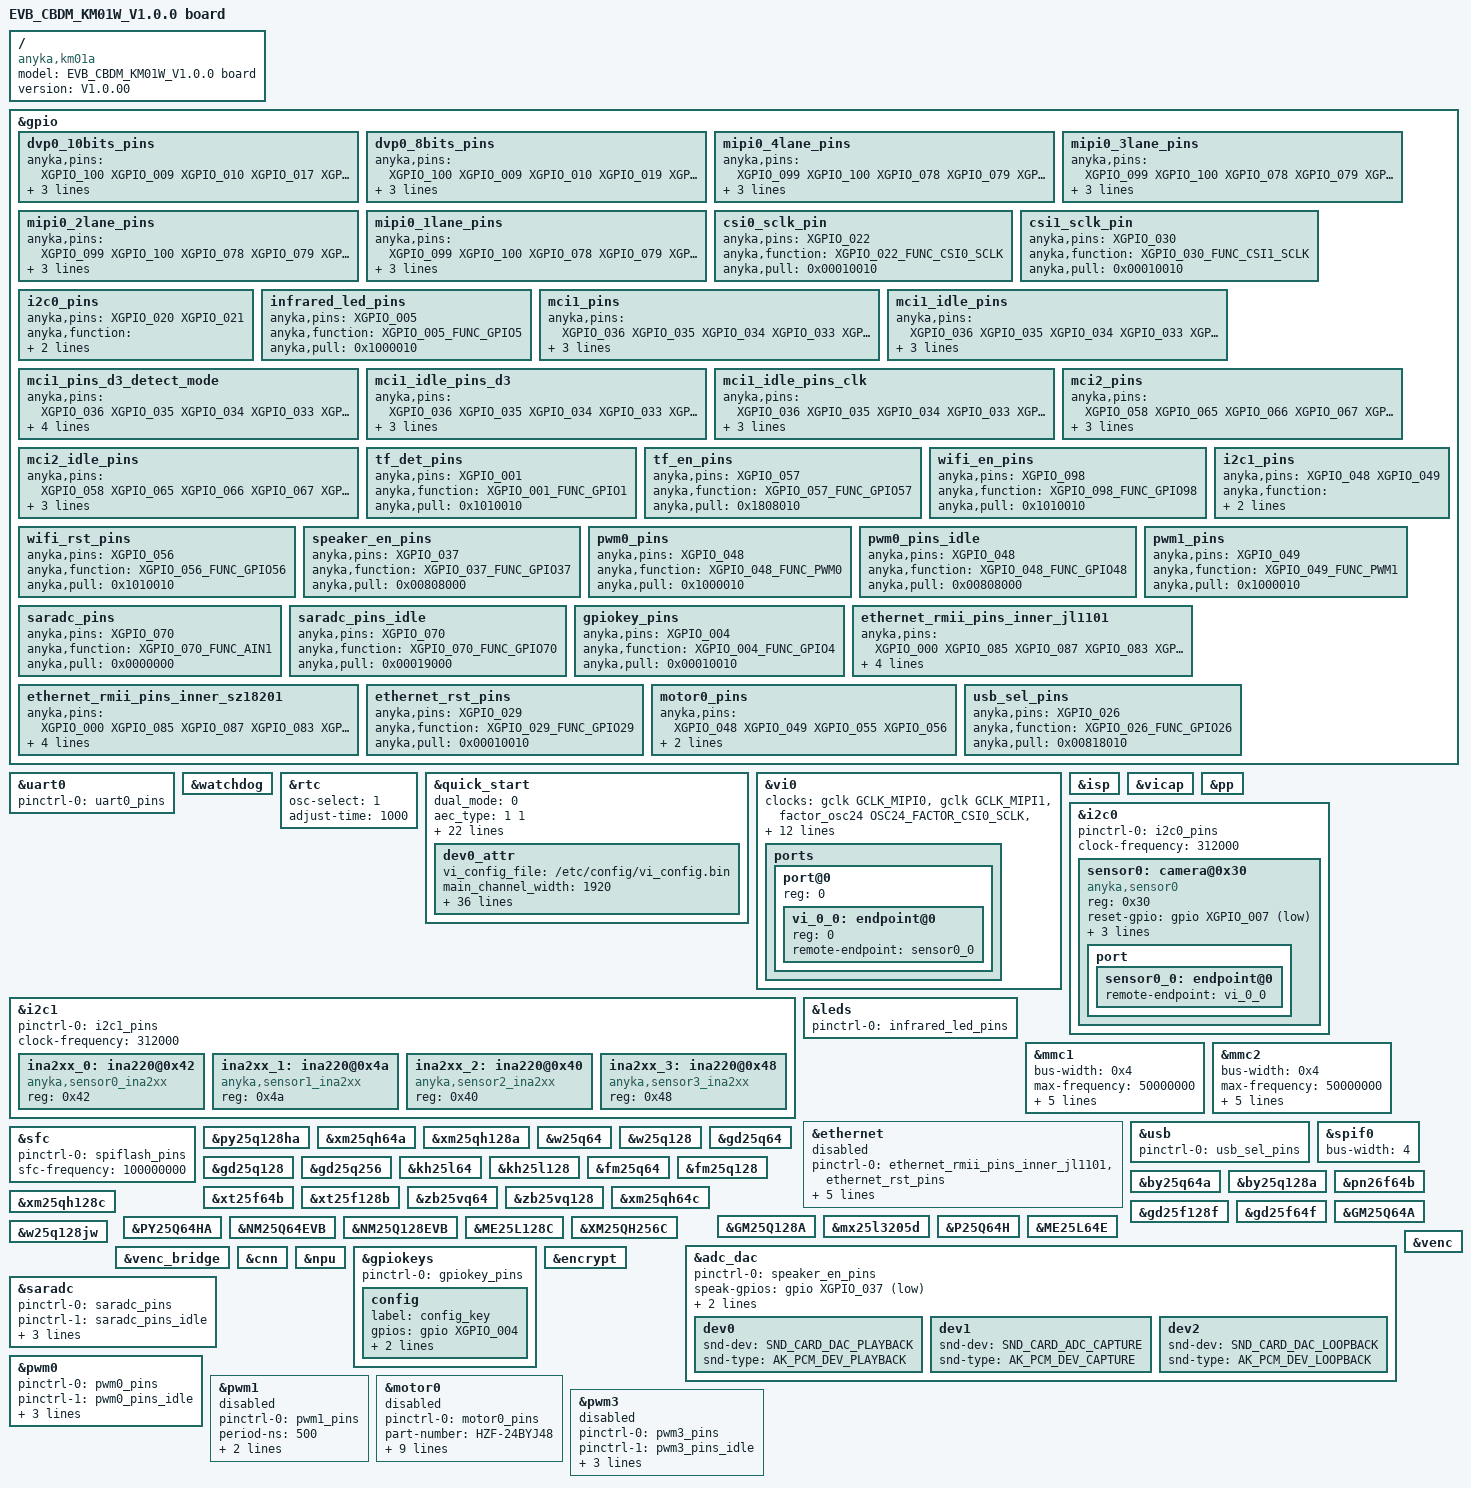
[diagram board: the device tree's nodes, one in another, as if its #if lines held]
/*
 * KM01W dev board dts
 *
 * Copyright (C) 2020 Anyka(Guangzhou) Microelectronics Technology Co., Ltd.
 *
 * This program is free software; you can redistribute it and/or modify
 * it under the terms of the GNU General Public License as published by
 * the Free Software Foundation; either version 2 of the License, or
 * (at your option) any later version.
 *
 * This program is distributed in the hope that it will be useful,
 * but WITHOUT ANY WARRANTY; without even the implied warranty of
 * MERCHANTABILITY or FITNESS FOR A PARTICULAR PURPOSE.  See the
 * GNU General Public License for more details.
 */

/dts-v1/;
#include "anycloud_km01a.dtsi"
#include "anycloud_norflash.dtsi"
//#include "anycloud_nandflash.dtsi"

/ {
    compatible = "anyka,km01a";
    model = "EVB_CBDM_KM01W_V1.0.0 board";
    version = "V1.0.00";
};

&gpio {
    /*
    * "anyka,function": func index, please refer to dt-bindings/pinctrl/ak3918av100_pinctrl.h
    * "anyka,pull": configuration of the pins
    * bit[7:0]: pull up/down configuration
    *     bit[0]: pull up or pull down selection, 1 means select pull down, 0 means select pull up
    *     bit[4]: pull up or pull down enable, 1 means enable pull up&down function, 0 means disable fuction
    * !!! Notice that not all pin support pull up and pull down. Please refer to the programer's guide.
    * bit[11:8]: driver strength configuration.
    *     bit[9:8] drive strength.
    * bit[12:15] gpio direction
    *     bit[12]: direction. 0 is output, 1 is input
    *     bit[15]: enable direction. 1 is enable
    * bit[19:16]: input enable configuration
    *     bit[16]: 1 means enable input, 0 means disable input.
    * bit[20-23]: gpio output level
    *     bit[20]: 0 is low level, 1 is high level
    *     bit[23]: enable gpio output level. 1 is enable
    * bit[31:24]: pin slew rate configuration
    *     bit[24]: 1 means fast slew rate, 0 means slow slew rate.
    * !!! Notice OTHER bits which not mentioned please set to 0.
    */

    dvp0_10bits_pins: dvp0_10bits_pins {
        anyka,pins = <XGPIO_100		//pclk
                         XGPIO_009	//hsync
                         XGPIO_010	//vsync
                         XGPIO_017	//d0
                         XGPIO_018  //d1
                         XGPIO_019	//d2
                         XGPIO_020	//d3
                         XGPIO_023	//d4
                         XGPIO_021	//d5
                         XGPIO_078	//d6
                         XGPIO_099	//d7
                         XGPIO_102	//d8
                         XGPIO_101>;//d9

        anyka,function = <XGPIO_100_FUNC_CSI_CLK
                            XGPIO_009_FUNC_CSI_HSYNC
                            XGPIO_010_FUNC_CSI_VSYNC
                            XGPIO_017_FUNC_CSI_D0
                            XGPIO_018_FUNC_CSI_D1
                            XGPIO_019_FUNC_CSI_D2
                            XGPIO_020_FUNC_CSI_D3
                            XGPIO_023_FUNC_CSI_D4
                            XGPIO_021_FUNC_CSI_D5
                            XGPIO_078_FUNC_CSI_D6
                            XGPIO_099_FUNC_CSI_D7
                            XGPIO_102_FUNC_CSI_D8
                            XGPIO_101_FUNC_CSI_D9>;
        anyka,pull = <0x00010010>;
    };

    dvp0_8bits_pins: dvp0_8bits_pins {
        anyka,pins = <   XGPIO_100
                         XGPIO_009
                         XGPIO_010
                         XGPIO_019	//d2
                         XGPIO_020	//d3
                         XGPIO_023	//d4
                         XGPIO_021	//d5
                         XGPIO_078	//d6
                         XGPIO_099	//d7
                         XGPIO_102	//d8
                         XGPIO_101>;//d9
        anyka,function = <  XGPIO_100_FUNC_CSI_CLK
                            XGPIO_009_FUNC_CSI_HSYNC
                            XGPIO_010_FUNC_CSI_VSYNC
                            XGPIO_019_FUNC_CSI_D2
                            XGPIO_020_FUNC_CSI_D3
                            XGPIO_023_FUNC_CSI_D4
                            XGPIO_021_FUNC_CSI_D5
                            XGPIO_078_FUNC_CSI_D6
                            XGPIO_099_FUNC_CSI_D7
                            XGPIO_102_FUNC_CSI_D8
                            XGPIO_101_FUNC_CSI_D9>;
        anyka,pull = <0x00010010>;
    };

	mipi0_4lane_pins: mipi0_4lane_pins {
		anyka,pins = <XGPIO_099
                        XGPIO_100
                        XGPIO_078
                        XGPIO_079
                        XGPIO_101
                        XGPIO_102
						XGPIO_103
                        XGPIO_104
						XGPIO_072
                        XGPIO_073>;
        anyka,function = <XGPIO_099_FUNC_MIPI_RX_L0P
                            XGPIO_100_FUNC_MIPI_RX_L0N
                            XGPIO_078_FUNC_MIPI_RX_L1P
                            XGPIO_079_FUNC_MIPI_RX_L1N
                            XGPIO_101_FUNC_MIPI_RX_L2P
                            XGPIO_102_FUNC_MIPI_RX_L2N
							XGPIO_103_FUNC_MIPI_RX_L3P
							XGPIO_104_FUNC_MIPI_RX_L3N
							XGPIO_072_FUNC_MIPI_RX_L4P
							XGPIO_073_FUNC_MIPI_RX_L4N>;
        anyka,pull = <0x00010010>;
	};

	mipi0_3lane_pins: mipi0_3lane_pins {
		anyka,pins = <XGPIO_099
                        XGPIO_100
                        XGPIO_078
                        XGPIO_079
                        XGPIO_101
                        XGPIO_102
						XGPIO_103
                        XGPIO_104
						XGPIO_072
                        XGPIO_073>;
        anyka,function = <XGPIO_099_FUNC_MIPI_RX_L0P
                            XGPIO_100_FUNC_MIPI_RX_L0N
                            XGPIO_078_FUNC_MIPI_RX_L1P
                            XGPIO_079_FUNC_MIPI_RX_L1N
                            XGPIO_101_FUNC_MIPI_RX_L2P
                            XGPIO_102_FUNC_MIPI_RX_L2N
							XGPIO_103_FUNC_MIPI_RX_L3P
							XGPIO_104_FUNC_MIPI_RX_L3N
							XGPIO_072_FUNC_MIPI_RX_L4P
							XGPIO_073_FUNC_MIPI_RX_L4N>;
        anyka,pull = <0x00010010>;
	};

	mipi0_2lane_pins: mipi0_2lane_pins {
		anyka,pins = <XGPIO_099
                        XGPIO_100
                        XGPIO_078
                        XGPIO_079
                        XGPIO_101
                        XGPIO_102>;
        anyka,function = <XGPIO_099_FUNC_MIPI_RX_L0P
                            XGPIO_100_FUNC_MIPI_RX_L0N
                            XGPIO_078_FUNC_MIPI_RX_L1P
                            XGPIO_079_FUNC_MIPI_RX_L1N
                            XGPIO_101_FUNC_MIPI_RX_L2P
                            XGPIO_102_FUNC_MIPI_RX_L2N>;
        anyka,pull = <0x00010010>;
	};

	mipi0_1lane_pins: mipi0_1lane_pins {
		anyka,pins = <XGPIO_099
                        XGPIO_100
                        XGPIO_078
                        XGPIO_079
                        XGPIO_101
                        XGPIO_102>;
        anyka,function = <XGPIO_099_FUNC_MIPI_RX_L0P
                            XGPIO_100_FUNC_MIPI_RX_L0N
                            XGPIO_078_FUNC_MIPI_RX_L1P
                            XGPIO_079_FUNC_MIPI_RX_L1N
                            XGPIO_101_FUNC_MIPI_RX_L2P
                            XGPIO_102_FUNC_MIPI_RX_L2N>;
        anyka,pull = <0x00010010>;
	};

    csi0_sclk_pin: csi0_sclk_pin {
        anyka,pins = <XGPIO_022>;
        anyka,function = <XGPIO_022_FUNC_CSI0_SCLK>;
        anyka,pull = <0x00010010>;
    };

    csi1_sclk_pin: csi1_sclk_pin {
        anyka,pins = <XGPIO_030>;
        anyka,function = <XGPIO_030_FUNC_CSI1_SCLK>;
        anyka,pull = <0x00010010>;
    };

    i2c0_pins: i2c0_pins {
        anyka,pins = <XGPIO_020 XGPIO_021>;
        anyka,function = <XGPIO_020_FUNC_TWI0_SDA XGPIO_021_FUNC_TWI0_SCL>;
        anyka,pull = <0x1010010>;
    };

    infrared_led_pins: infrared_led_pins {
        anyka,pins = <XGPIO_005>;
        anyka,function = <XGPIO_005_FUNC_GPIO5>;
        anyka,pull = <0x1000010>;
    };
/*
    state_led_pin: state_led_pin {
        anyka,pins = <XGPIO_005>;
        anyka,function = <XGPIO_005_FUNC_GPIO5>;
        anyka,pull = <0x1000010>;
    };
*/
    mci1_pins: mci1_pins {
        anyka,pins = <XGPIO_036
                        XGPIO_035
                        XGPIO_034
                        XGPIO_033
                        XGPIO_032
                        XGPIO_031>;
        anyka,function = <XGPIO_036_FUNC_SDIO0_DATA1
                            XGPIO_035_FUNC_SDIO0_DATA0
                            XGPIO_034_FUNC_SDIO0_MCLK
                            XGPIO_033_FUNC_SDIO0_CMD
                            XGPIO_032_FUNC_SDIO0_DATA3
                            XGPIO_031_FUNC_SDIO0_DATA2>;
        anyka,pull = <0x10010>;
    };

    /*
       when not use tf card, set to idle state,
       to protect tf card and extend it's life.
    */
    mci1_idle_pins: mci1_idle_pins {
        anyka,pins = <XGPIO_036
                        XGPIO_035
                        XGPIO_034
                        XGPIO_033
                        XGPIO_032
                        XGPIO_031>;
        anyka,function = <XGPIO_036_FUNC_GPIO36
                            XGPIO_035_FUNC_GPIO35
                            XGPIO_034_FUNC_GPIO34
                            XGPIO_033_FUNC_GPIO33
                            XGPIO_032_FUNC_GPIO32
                            XGPIO_031_FUNC_GPIO31>;
        anyka,pull = <0x11>;
    };

    /* 
     *  When using DATA3 as plugin and plugoff detect:
     *  1. Set XGPIO_032_FUNC_SDIO0_DATA3 pull up disable and pull down disable
     *  2. Using PULLDOWN RESISTANCE on PCB, for example, 510   KΩ.
    */      
    mci1_pins_d3_detect_mode: mci1_pins_d3_detect_mode {
        anyka,pins = <XGPIO_036
                        XGPIO_035
                        XGPIO_034
                        XGPIO_033
                        XGPIO_032
                        XGPIO_031>;
        anyka,function = <XGPIO_036_FUNC_SDIO0_DATA1
                            XGPIO_035_FUNC_SDIO0_DATA0
                            XGPIO_034_FUNC_SDIO0_MCLK
                            XGPIO_033_FUNC_SDIO0_CMD
                            XGPIO_032_FUNC_SDIO0_DATA3
                            XGPIO_031_FUNC_SDIO0_DATA2>;
        anyka,pull = <  0x10010 
                        0x10010
                        0x10010
                        0x10010
                        0x10001  /* disable pull down and pull up */
                        0x10010 >;
    };

    /*
       when not use tf card, set to idle state, the pin set to gpio function except dat3 pin.
       to protect tf card, extend it's life.
    */
    mci1_idle_pins_d3: mci1_idle_pins_d3 {
        anyka,pins = <XGPIO_036
                        XGPIO_035
                        XGPIO_034
                        XGPIO_033
                        XGPIO_032
                        XGPIO_031>;
        anyka,function = <XGPIO_036_FUNC_GPIO36
                            XGPIO_035_FUNC_GPIO35
                            XGPIO_034_FUNC_GPIO34
                            XGPIO_033_FUNC_GPIO33
                            XGPIO_032_FUNC_SDIO0_DATA3
                            XGPIO_031_FUNC_GPIO31>;
        anyka,pull = <  0x11
                        0x11
                        0x11
                        0x11
                        0x10001  /* disable pull down and pull up */
                        0x11 >;
    };

    /*
       when not use tf card, set to idle state, the pin set to gpio function except mclk pin.
       to protect tf card, extend it's life.
    */
    mci1_idle_pins_clk: mci1_idle_pins_clk {
        anyka,pins = <XGPIO_036
                        XGPIO_035
                        XGPIO_034
                        XGPIO_033
                        XGPIO_032
                        XGPIO_031>;
        anyka,function = <XGPIO_036_FUNC_GPIO36
                            XGPIO_035_FUNC_GPIO35
                            XGPIO_034_FUNC_SDIO0_MCLK
                            XGPIO_033_FUNC_GPIO33
                            XGPIO_032_FUNC_GPIO32
                            XGPIO_031_FUNC_GPIO31>;
        anyka,pull = <  0x11
                        0x11
                        0x10010 /* clk */
                        0x11
                        0x11
                        0x11 >;
    };

    mci2_pins: mci2_pins {
        anyka,pins = <XGPIO_058
                     XGPIO_065
                     XGPIO_066
                     XGPIO_067
                     XGPIO_068
                     XGPIO_069>;
        anyka,function = <  XGPIO_058_FUNC_SDIO1_CMD
                        XGPIO_065_FUNC_SDIO1_MCLK
                        XGPIO_066_FUNC_SDIO1_DATA2
                        XGPIO_067_FUNC_SDIO1_DATA3
                        XGPIO_068_FUNC_SDIO1_DATA0
                        XGPIO_069_FUNC_SDIO1_DATA1>;
        anyka,pull = <0x10010>;
    };

    mci2_idle_pins: mci2_idle_pins {
        anyka,pins = <  XGPIO_058
                        XGPIO_065
                        XGPIO_066
                        XGPIO_067
                        XGPIO_068
                        XGPIO_069>;
        anyka,function = <  XGPIO_058_FUNC_GPIO58
                            XGPIO_065_FUNC_GPIO65
                            XGPIO_066_FUNC_GPIO66
                            XGPIO_067_FUNC_GPIO67
                            XGPIO_068_FUNC_GPIO68
                            XGPIO_069_FUNC_GPIO69>;
        anyka,pull = <0x0>;

    };

    tf_det_pins: tf_det_pins {
        anyka,pins = <XGPIO_001>;
        anyka,function = <XGPIO_001_FUNC_GPIO1>;
        anyka,pull = <0x1010010>;
    };

    tf_en_pins: tf_en_pins {
        anyka,pins = <XGPIO_057>;
        anyka,function = <XGPIO_057_FUNC_GPIO57>;
        anyka,pull = <0x1808010>;
    };

    wifi_en_pins: wifi_en_pins {
        anyka,pins = <XGPIO_098>;
        anyka,function = <XGPIO_098_FUNC_GPIO98>;
        anyka,pull = <0x1010010>;
    };

    wifi_rst_pins: wifi_rst_pins {
        anyka,pins = <XGPIO_056>;
        anyka,function = <XGPIO_056_FUNC_GPIO56>;
        anyka,pull = <0x1010010>;
    };

    speaker_en_pins: speaker_en_pins {
        anyka,pins = <XGPIO_037>;
        anyka,function = <XGPIO_037_FUNC_GPIO37>;
        anyka,pull = <0x00808000>;
    };

    i2c1_pins: i2c1_pins {
        anyka,pins = <XGPIO_048 XGPIO_049>;
        anyka,function = <XGPIO_048_FUNC_TWI1_SCL XGPIO_049_FUNC_TWI1_SDA>;
        anyka,pull = <0x1010010>;
    };

    pwm0_pins: pwm0_pins {
        anyka,pins = <XGPIO_048>;
        anyka,function = <XGPIO_048_FUNC_PWM0>;
        anyka,pull = <0x1000010>;
    };

    pwm0_pins_idle: pwm0_pins_idle {
        anyka,pins = <XGPIO_048>;
        anyka,function = <XGPIO_048_FUNC_GPIO48>;
        anyka,pull = <0x00808000>;
    };

    pwm1_pins: pwm1_pins {
        anyka,pins = <XGPIO_049>;
        anyka,function = <XGPIO_049_FUNC_PWM1>;
        anyka,pull = <0x1000010>;
    };

    saradc_pins: saradc_pins {
        anyka,pins = <XGPIO_070>;
        anyka,function = <XGPIO_070_FUNC_AIN1>;
        anyka,pull = <0x0000000>;
    };

    saradc_pins_idle: saradc_pins_idle {
        anyka,pins = <XGPIO_070>;
        anyka,function = <XGPIO_070_FUNC_GPIO70>;
        anyka,pull = <0x00019000>;
    };

	gpiokey_pins:gpiokey_pins {
		anyka,pins = <XGPIO_004>;
		anyka,function = <XGPIO_004_FUNC_GPIO4>;
		anyka,pull = <0x00010010>;
	};

    ethernet_rmii_pins_inner_jl1101: ethernet_rmii_pins_inner_jl1101 {
        anyka,pins = <  XGPIO_000
                        XGPIO_085
                        XGPIO_087
                        XGPIO_083
                        XGPIO_084
                        XGPIO_091
                        XGPIO_088
                        XGPIO_082
                        XGPIO_089
                        XGPIO_090
                        XGPIO_086
                        XGPIO_028
                    >;
        anyka,function = <  XGPIO_000_FUNC_OPCLK1
                            XGPIO_085_FUNC_RMII_MDIO    
                            XGPIO_087_FUNC_RMII_MDC    
                            XGPIO_083_FUNC_RMII_RXER
                            XGPIO_084_FUNC_RMII_RXDV
                            XGPIO_091_FUNC_RMII_RXD0    
                            XGPIO_088_FUNC_RMII_RXD1    
                            XGPIO_082_FUNC_GPIO82 
                            XGPIO_089_FUNC_RMII_TXD0   
                            XGPIO_090_FUNC_RMII_TXD1    
                            XGPIO_086_FUNC_RMII_TXEN    
                            XGPIO_028_FUNC_MAC_PHY_25M  
                        >;
        /* anyka,pull is the same as AV100N expect XGPIO_028_FUNC_MAC_PHY_25M */
        anyka,pull = <  0x00010000 /* XGPIO_000_FUNC_OPCLK1, input enable */
                        0x00010010 /* XGPIO_085_FUNC_RMII_MDIO, input enable, driver 2mA, slow slew rate, pull up enable*/
                        0x00010011 /* XGPIO_087_FUNC_RMII_MDC,  input enable, driver 2mA, slow slew rate, pull down enable*/
                        0x00010011 /* XGPIO_083_FUNC_RMII_RXER, input enable, driver 2mA, slow slew rate, pull down enable*/
                        0x00010011 /* XGPIO_084_FUNC_RMII_RXDV, input enable, driver 2mA, slow slew rate, pull down enable*/
                        0x00010011 /* XGPIO_091_FUNC_RMII_RXD0, input enable, driver 2mA, slow slew rate, pull down enable*/
                        0x00010011 /* XGPIO_088_FUNC_RMII_RXD1, input enable, driver 2mA, slow slew rate, pull down enable*/ 
                        0x00019000 /* XGPIO_082_FUNC_GPIO82, input state */
                        0x01010011 /* XGPIO_089_FUNC_RMII_TXD0, input enable, driver 2mA, fast slew rate, pull down enable*/ 
                        0x01010011 /* XGPIO_090_FUNC_RMII_TXD1, input enable, driver 2mA, fast slew rate, pull down enable*/ 
                        0x00010011 /* XGPIO_086_FUNC_RMII_TXEN, input enable, driver 2mA, slow slew rate, pull down enable*/            
                        0x00010010 /* XGPIO_028_FUNC_MAC_PHY_25M (clk for phy), input enable, driver 2mA, slow slew rate, pull up enable*/  
                    >;  
    };

    ethernet_rmii_pins_inner_sz18201: ethernet_rmii_pins_inner_sz18201 {
        anyka,pins = <  XGPIO_000
                        XGPIO_085
                        XGPIO_087
                        XGPIO_083
                        XGPIO_084
                        XGPIO_091
                        XGPIO_088
                        XGPIO_082
                        XGPIO_089
                        XGPIO_090
                        XGPIO_086
                        XGPIO_028
                    >;
        anyka,function = <  XGPIO_000_FUNC_OPCLK1
                            XGPIO_085_FUNC_RMII_MDIO    
                            XGPIO_087_FUNC_RMII_MDC    
                            XGPIO_083_FUNC_RMII_RXER
                            XGPIO_084_FUNC_RMII_RXDV
                            XGPIO_091_FUNC_RMII_RXD0    
                            XGPIO_088_FUNC_RMII_RXD1    
                            XGPIO_082_FUNC_GPIO82 
                            XGPIO_089_FUNC_RMII_TXD0   
                            XGPIO_090_FUNC_RMII_TXD1    
                            XGPIO_086_FUNC_RMII_TXEN    
                            XGPIO_028_FUNC_MAC_PHY_25M  
                        >;
        /* anyka,pull is the same as AV100N expect XGPIO_028_FUNC_MAC_PHY_25M */
        anyka,pull = <  0x00010000 /* XGPIO_000_FUNC_OPCLK1, input enable */
                        0x00010010 /* XGPIO_085_FUNC_RMII_MDIO, input enable, driver 2mA, slow slew rate, pull up enable*/
                        0x00010011 /* XGPIO_087_FUNC_RMII_MDC,  input enable, driver 2mA, slow slew rate, pull down enable*/
                        0x00010011 /* XGPIO_083_FUNC_RMII_RXER, input enable, driver 2mA, slow slew rate, pull down enable*/
                        0x00010011 /* XGPIO_084_FUNC_RMII_RXDV, input enable, driver 2mA, slow slew rate, pull down enable*/
                        0x00010011 /* XGPIO_091_FUNC_RMII_RXD0, input enable, driver 2mA, slow slew rate, pull down enable*/
                        0x00010011 /* XGPIO_088_FUNC_RMII_RXD1, input enable, driver 2mA, slow slew rate, pull down enable*/ 
                        0x00019000 /* XGPIO_082_FUNC_GPIO82, input state */
                        0x01010011 /* XGPIO_089_FUNC_RMII_TXD0, input enable, driver 2mA, fast slew rate, pull down enable*/ 
                        0x01010011 /* XGPIO_090_FUNC_RMII_TXD1, input enable, driver 2mA, fast slew rate, pull down enable*/ 
                        0x00010011 /* XGPIO_086_FUNC_RMII_TXEN, input enable, driver 2mA, slow slew rate, pull down enable*/            
                        0x00010010 /* XGPIO_028_FUNC_MAC_PHY_25M (clk for phy), input enable, driver 2mA, slow slew rate, pull up enable*/  
                    >;  
    };

    ethernet_rst_pins: ethernet_rst_pins {
        anyka,pins = <XGPIO_029>;
        anyka,function = <XGPIO_029_FUNC_GPIO29>;
        anyka,pull = <0x00010010>;
    };
    
    motor0_pins: motor0_pins {
         anyka,pins = <XGPIO_048 XGPIO_049 XGPIO_055 XGPIO_056>;    
         anyka,function = <0>;    
         anyka,pull = <0x00000010>;    
    };

    usb_sel_pins: usb_sel_pins {
        anyka,pins = <XGPIO_026>;
        anyka,function = <XGPIO_026_FUNC_GPIO26>;
        anyka,pull = <0x00818010>;
    };
 };

&uart0 {
    pinctrl-names = "default";
    pinctrl-0 = <&uart0_pins>;
    status = "okay";
};

&watchdog {
    status = "okay";
};

&rtc {
    /*
     * rtc osc-select, 1 means INTERNAL RC OSC, 0 means EXTERNAL XTAL
     * if internal RC OSC is used to generate 32KH,time adjustment should be setting.(basic unit: ms)
     * AV100P/X only support internal RC OSC.
     */
    osc-select = <1>;
    adjust-time = <1000>;
    //adjust-based-on-timer;
    status = "okay";
};

&quick_start {
    dual_mode = <0>;/*dual mode*/
	/* aec work type: 0, manual; 1, auto*/
	aec_type = <1 1>; /*<dev_0 dev_1 ..dev_n>*/
	ae_table_file = "/etc/config/lumi_ae_table.bin";
    fastae_mode = <0>;/* mode with two bit*/
    				  /* 0 bit[00]: without ae_table */
    				  /* 1 bit[01]: only enable soft ae_table */
    				  /* 2 bit[10]: only enable hw ae_table */
    				  /* 3 bit[11]: enable hw and soft ae_table, use soft to fix hw limit */
	day2night_threshold = <900>; /* when fastae_mode is 2 or 3, set to 82(adc value), else set to 900 (env=ae/lumi)*/
	night2day_threshold = <800>;
	bining_mode = <1>;/*1 enable bining mode, 0:disable*/
	ae_stable_range = <6>; /*假设目标亮度为40lumi, 则收敛到[34,46]区间内即算稳定，开始送编码*/
	set_3dnr_size = <0>;/*usr config 3dnr size, KB*/

	/*light_sensor*/
    ain_index =  <1>;/*1 --> ain1*/

    /* set ircut to default status at kernel init. 0: not set, 1: init. */
    ircut_set_to_default = <1>;

	status = "okay";
	
	venc_chn0_bind_vi_chn = <0>; /*0 : VIDEO_CHN0 */
	venc_chn0_width = <1920>;
	venc_chn0_height = <1080>;
	venc_chn0_fps = <15>;
	venc_chn0_profile = <0>; /*0:H264-main, 4: H265-main, 8:JPEG*/
	venc_chn0_br_mode = <4>; /*0:cbr, 1: vbr, 4:avbr*/
	venc_chn0_initqp = <100>;
	venc_chn0_minqp = <25>;
	venc_chn0_maxqp = <48>;
	venc_chn0_maxbitrate = <1024>;
	venc_chn0_enc_level = <50>;
	venc_chn0_enc_out_type = <0>; /* 0:H264, 1:JPEG, 2:H265 */
	venc_chn0_max_frame_size = <0>; /* output stream buf szie(KB), 0: use default size */

	dev0_attr{
		vi_config_file = "/etc/config/vi_config.bin";
		//main chn info
		main_channel_width = <1920>;
		main_channel_height = <1080>;
		main_venc_mode = <1>;/*0:encode frame in user layer, 1:encode frame in kernel layer;*/
		main_chn_mode = <0>;/*0->fream, 1->slice*/
		main_chn_buf = <3>;/*fream:yuv buffer,  slice:slice num*/

		//sub chn info
		sub_channel_width = <640>;
		sub_channel_height = <360>;
		sub_venc_mode = <1>;/*0:encode frame in user layer, 1:encode frame in kernel layer;*/
		sub_chn_mode = <0>;/*0->fream, only frame*/
		sub_chn_buf = <2>;/*fream:yuv buffer*/

		//thd chn info
		third_channel_width = <320>;
		third_channel_height = <180>;
		thd_encode_mode = <1>;/*0:encode frame in user layer, 1:encode frame in kernel layer;*/
		thd_chn_mode = <0>;/*0->fream, only frame*/
		thd_chn_buf = <2>;/*fream:yuv buffer*/

		crop_left = <0>;
		crop_top = <0>;
		crop_width = <0>;
		crop_height = <0>;

		//main chn crop info
		main_crop_left = <0>;
		main_crop_top = <0>;
		main_crop_width = <0>;
		main_crop_height = <0>;

		//sub chn crop info
		sub_crop_left = <0>;
		sub_crop_top = <0>;
		sub_crop_width = <0>;
		sub_crop_height = <0>;

		//thd chn crop info
		thd_crop_left = <0>;
		thd_crop_top = <0>;
		thd_crop_width = <0>;
		thd_crop_height = <0>;
			
		day_night_mode_select = <0>; /* 0:irfeed light; 1: white light; 2: always day mode with light off;  3: always night mode with light on; 4: always day mode with light on;*/
		ircut_a_gpio = <&gpio XGPIO_008 1>;//1:day, 0:night
		ircut_b_gpio = <&gpio XGPIO_004 1>;
		irled_gpio = <&gpio XGPIO_011 1>;
		whiteled_gpio = <&gpio 0xffff 0>;

		isp_cfg_file = "/mnt/isp.conf";
	};

};

&vi0{
	clocks =  
		  /*<&factor_pll3_clk  PLL3_FACTOR_ISP>,*/
		  /*<&factor_pll2_clk  PLL2_FACTOR_ISP>,*/
		 /* <&isp_mux_clk>,*/
		  <&gclk GCLK_MIPI0>,
		  <&gclk GCLK_MIPI1>,
		  <&factor_osc24    OSC24_FACTOR_CSI0_SCLK>,
		  /*<&factor_osc24    OSC24_FACTOR_CSI1_SCLK>,*/
		  <&factor_pll1_clk  PLL1_FACTOR_ISP>,
		  /*<&factor_pll2_clk  PLL2_FACTOR_ISP>,*/
		  /*<&factor_pll3_clk  PLL3_FACTOR_ISP>,*/
		  <&factor_pll1_clk  PLL1_FACTOR_PP>,
		  <&factor_pll2_clk PLL2_FACTOR_DPHY_CFGCLK>;	

    clock-names =   /*"isp_clk", */
					"mipi0_gclk",
					"mipi1_gclk",
					"csi0_sclk",
					/*"csi1_sclk",*/
					"pll1_isp", 
				   /*"pll2_isp", */
				   /* "pll3_isp",*/
					"pll1_pp",
					"pll2_dphy";

    pinctrl-names =
        "mipi0_4lane",
        "mipi0_3lane",
        "mipi0_2lane",
        "mipi0_1lane",
        "csi0_sclk";
    pinctrl-0 = <&mipi0_4lane_pins>;
    pinctrl-1 = <&mipi0_3lane_pins>;
    pinctrl-2 = <&mipi0_2lane_pins>;
    pinctrl-3 = <&mipi0_1lane_pins>;
    pinctrl-4 = <&csi0_sclk_pin>;

	csi_mipi_lane_swap = <
		SENSOR_D0	//L0
		SENSOR_C0	//L1
		SENSOR_D1	//L2
		SENSOR_D2	//L3
		SENSOR_D3	//L4
		SENSOR_C1	//L5
		>;//MIPI_RX_L0~5.

	csi_mipi_dndp_swap = <
		MIPI_DNDP_NOSWAP	//L0
		MIPI_DNDP_NOSWAP	//L1
		MIPI_DNDP_NOSWAP	//L2
		MIPI_DNDP_NOSWAP	//L3
		MIPI_DNDP_NOSWAP	//L4
		MIPI_DNDP_NOSWAP	//L5
	>;//MIPI_RX_L0~5. 0: noswap; others: swap

    status = "okay";

	ports {
		#address-cells = <1>;
		#size-cells = <0>;

		port@0 {
			#address-cells = <1>;
			#size-cells = <0>;
			reg = <0>;

			vi_0_0: endpoint@0 {
				reg = <0>;
				remote-endpoint = <&sensor0_0>;
			};
		};
	};
};

&isp {
    status = "okay";
};

&vicap {
    status = "okay";
};

&pp {
    status = "okay";
};


&i2c0 {
    pinctrl-names = "default";
    pinctrl-0 = <&i2c0_pins>;
    
    clock-frequency = <312000>;
    status = "okay";
	#address-cells = <1>;
	#size-cells = <0>;
    
	sensor0: camera@0x30{
		compatible = "anyka,sensor0";
		reg = <0x30>;

		/*0xffff means the gpio is invalid*/
		reset-gpio = <&gpio XGPIO_007 1>;
		pwdn-gpio = <&gpio XGPIO_018 1>;
		fsync-gpio = <&gpio 0xffff 1>;
		power-gpio = <&gpio 0xffff 1>;

		port {
			sensor0_0: endpoint@0 {
				remote-endpoint = <&vi_0_0>;
			};
		};
	};
};

#ifdef AK_PWR_CONSUMPTION_TEST
&i2c1 {
    pinctrl-names = "default";
    pinctrl-0 = <&i2c1_pins>;
    clock-frequency = <312000>;
    status = "okay";
	#address-cells = <1>;
	#size-cells = <0>;

	ina2xx_0: ina220@0x42{
		compatible = "anyka,sensor0_ina2xx";
		reg = <0x42>;
	};

	ina2xx_1: ina220@0x4a{
		compatible = "anyka,sensor1_ina2xx";
		reg = <0x4a>;
	};

	ina2xx_2: ina220@0x40{
		compatible = "anyka,sensor2_ina2xx";
		reg = <0x40>;
	};

	ina2xx_3: ina220@0x48{
		compatible = "anyka,sensor3_ina2xx";
		reg = <0x48>;
	};
};
#else
&i2c1 {
    pinctrl-names = "default";
    pinctrl-0 = <&i2c1_pins>;
    clock-frequency = <312000>;
    status = "disable";
	#address-cells = <1>;
	#size-cells = <0>;
};
#endif

&leds {
    pinctrl-names = "default";
    //pinctrl-0 = <&infrared_led_pins>,<&state_led_pin>;
	pinctrl-0 = <&infrared_led_pins>;
    status = "okay";
/*
    ir_led {
        label = "irled";
        gpios = <&gpio XGPIO_005 GPIO_ACTIVE_HIGH>;
    };

    state_led {
        label = "state_led";
        gpios = <&gpio XGPIO_005 GPIO_ACTIVE_HIGH>;
    };
*/
};

/* mmc1 card detect using detect-gpio or detect-gpios */
&mmc1 {
    bus-width = <0x4>;
    max-frequency = <50000000>;
    detect-gpio = <&gpio XGPIO_001 1>;
    cap-sd-highspeed;
    pinctrl-names = "default","idle";
    pinctrl-0 = <&mci1_pins>,<&tf_en_pins>,<&tf_det_pins>;
    pinctrl-1 = <&mci1_idle_pins>; 
    power-pins = <&gpio XGPIO_057 1>;
    status = "okay"; 
};

/* mmc1 card detect using cd_clk */
/*
&mmc1 {
    bus-width = <0x4>;
    max-frequency = <50000000>;
    cd_clk;
    cap-sd-highspeed;
    pinctrl-names = "default","idle";
    pinctrl-0 = <&mci1_pins>,<&tf_en_pins>;
    pinctrl-1 = <&mci1_idle_pins_clk>;
    power-pins = <&gpio XGPIO_000 1>;
    status = "okay"; 
};
*/

/* mmc1 card detect using cd_d3 */
/*
&mmc1 {
    bus-width = <0x4>;
    max-frequency = <50000000>;
    cd_d3;
    cap-sd-highspeed;
    pinctrl-names = "default","idle";
    pinctrl-0 = <&mci1_pins_d3_detect_mode>,<&tf_en_pins>;
    pinctrl-1 = <&mci1_idle_pins_d3>; 
    power-pins = <&gpio XGPIO_000 1>;
    status = "okay"; 
};
*/

&mmc2 {
    bus-width = <0x4>;
    max-frequency = <50000000>;
    non-removable;
    cap-sd-highspeed;
    /* if support sdio, using cap-sdio-irq*/
    cap-sdio-irq;
    pinctrl-names = "default","idle";
    pinctrl-0 = <&mci2_pins>;//,<&wifi_en_pins>,<&wifi_rst_pins>;
    pinctrl-1 = <&mci2_idle_pins>;
    //power-pins = <&gpio XGPIO_098 1>;   //power-pins is which wifi_en_pins describes
    //rst-pins =   <&gpio XGPIO_056 1>;    //rst-pins is which wifi_rst_pins describes
    status = "okay"; 
};

&ethernet {
    pinctrl-names = "default","inner_sz18201";
    pinctrl-0 = <&ethernet_rmii_pins_inner_jl1101 &ethernet_rst_pins>;
    pinctrl-1 = <&ethernet_rmii_pins_inner_sz18201 &ethernet_rst_pins>;
    reset-gpios = <&gpio XGPIO_029 1>;
    phy-address = <1>;
    inner-phy-mode = <1>;
    status = "disable";
};

&usb {
    pinctrl-names = "default";
    pinctrl-0 = <&usb_sel_pins>;
    status = "okay";
};

&sfc {
    pinctrl-names = "default";
    pinctrl-0 = <&spiflash_pins>;
    sfc-frequency = <100000000>;
    status = "okay";
};

&spif0 {
    /* spi flash data bus width:
    ** 1 means 1 wire mode.
    ** 2 means 2 wire mode
    ** 4 means 4 wire mode.
    ** default: 4 wire mode.
    **/
    bus-width = <4>;
    status = "okay";
};

&py25q128ha{
    status = "okay";
};

&xm25qh64a{
    status = "okay";
};

&xm25qh128a{
    status = "okay";
};

&w25q64{
    status = "okay";
};

&w25q128{
    status = "okay";
};

&gd25q64{
    status = "okay";
};

&gd25q128{
    status = "okay";
};

&gd25q256{
    status = "okay";
};

&kh25l64{
    status = "okay";
};

&kh25l128{
    status = "okay";
};

&fm25q64{
    status = "okay";
};

&fm25q128{
    status = "okay";
};

&by25q64a{
    status = "okay";
};

&by25q128a{
    status = "okay";
};

&pn26f64b{
    status = "okay";
};

&xt25f64b{
    status = "okay";
};

&xt25f128b{
    status = "okay";
};

&zb25vq64{
    status = "okay";
};

&zb25vq128{
    status = "okay";
};

&xm25qh64c{
    status = "okay";
};

&xm25qh128c{
    status = "okay";
};

&gd25f128f{
    status = "okay";
};

&gd25f64f{
    status = "okay";
};

//&GD5F1GQ5UEY1G{
//    status = "okay";
//};

//&GD5F2GQ5UEYIG{
//    status = "okay";
//};

//&FM25S02A{
//    status = "okay";
//};

//&W25N02KV{
//    status = "okay";
//};

//&FS35ND01G{
//    status = "okay";
//};

//&FS35ND02G{
//    status = "okay";
//};

//&MX35LF1GE4AB{
//    status = "okay";
//};

//&XT26G01C{
//    status = "okay";
//};

//&MX35LF2GE4AD{
//    status = "okay";
//};

//&XT26G02E{
//    status = "okay";
//};

&GM25Q64A{
    status = "okay";
};

&GM25Q128A{
    status = "okay";
};

&mx25l3205d{
    status = "okay";
};

&P25Q64H{
    status = "okay";
};

&PY25Q64HA{
  status = "okay";
};

&NM25Q64EVB{
    status = "okay";
};

&NM25Q128EVB{
    status = "okay";
};

&ME25L64E{
    status = "okay";
};

&ME25L128C{
    status = "okay";
};

&XM25QH256C{
    status = "okay";
};

&w25q128jw{
    status = "okay";
};

&adc_dac {
    pinctrl-names = "default";
    pinctrl-0 = <&speaker_en_pins>;
    speak-gpios = <&gpio XGPIO_037 1>;
    pd-hpvcm = <1>;
    /*
    * The level of speak-gpios votage for power on audio: 0=low, 1=high
    */
    speak-gpios-en = <1>;
    status = "okay";

    dev0 {
        snd-dev = <SND_CARD_DAC_PLAYBACK>;
        snd-type = <AK_PCM_DEV_PLAYBACK>;
    };

    dev1 {
        snd-dev = <SND_CARD_ADC_CAPTURE>;
        snd-type = <AK_PCM_DEV_CAPTURE>;
    };

    dev2 {
        snd-dev = <SND_CARD_DAC_LOOPBACK>;
        snd-type = <AK_PCM_DEV_LOOPBACK>;
    };
};

&venc {
    status = "okay";
};

&venc_bridge{
     status = "okay";
};

&cnn{
    status = "okay";
};

&npu{
    status = "okay";
};

&gpiokeys {
	#address-cells = <1>;
	#size-cells = <0>;
	pinctrl-0 = <&gpiokey_pins>;
	pinctrl-names = "default";
	status = "okay";

	config {
        label = "config_key";
        gpios = <&gpio XGPIO_004 GPIO_ACTIVE_HIGH>;
        linux,code = <116>;
        debounce-interval = <100>;
	};
};

&saradc{
    pinctrl-names = "default", "idle";
    pinctrl-0 = <&saradc_pins>;
    pinctrl-1 = <&saradc_pins_idle>;

    /* SAR ADC VREF selection
    * 0:To select AVCC 3.3V as VREF for SAR ADC.
    * 1:To select 3.0V generated from BGR as VREF for SAR ADC.
    */
    vref-select = <0>;
    /*
    * 0:To disable BAT voltage divider.
    * 1:To enable BAT voltage divider divided by 2.
    */
    battery-divider = <1>;
    /*
    * Sampling number
    * Read the sampling data for N times and then calculate the average value.
    * N ranges from 1 to 7.
    */
    sampling-num = <3>;
    status = "okay";
};

&encrypt{
    status = "okay"; 
};

&pwm0 {
	pinctrl-names = "default", "idle";
    pinctrl-0 = <&pwm0_pins>;
	pinctrl-1 = <&pwm0_pins_idle>;
	period-ns = <500>;
	duty-ns = <100>;
	pwm-enable = <1>;
	status = "okay";
};

&pwm1 {
	pinctrl-names = "default";
    pinctrl-0 = <&pwm1_pins>;
	period-ns = <500>;
	duty-ns = <250>;
	pwm-enable = <1>;
	status = "disable";
};

&motor0 {
	/*
	 * part-number: part name
	 * pwm-tbl-cw: pwm table int clkwise
	 * pwm-pins: gpio list to motor
	 * steps-one-circle: total steps one circle (360degree)
	 *
	 * total-steps:	total steps the motor can run
	 * boundary-steps: reserve some step for each boudary
	 * attach-timer: timer for the motor
	 *					NOTE: different motor attach different timer
	 *
	 * speed-step: speed in step
	 */

	pinctrl-names = "default";
	pinctrl-0 = <&motor0_pins>;

	part-number = "HZF-24BYJ48";
	pwm-tbl-cw = <0x09 0x01 0x03 0x02 0x06 0x04 0x0c 0x08>;
	pwm-pins = <XGPIO_048 XGPIO_049 XGPIO_055 XGPIO_056>;
	steps-one-circle = <4096>;
	total-steps = <2500>;
	boundary-steps = <50>;
	attach-timer = <2>; /*注意 time 0 ~ 4 系统用了time 0和time1*/

	speed-step = <200>;

	status = "disable";
};

&pwm3 {
    pinctrl-names = "default", "idle";
    pinctrl-0 = <&pwm3_pins>;
    pinctrl-1 = <&pwm3_pins_idle>;
    period-ns = <500>;
    duty-ns = <100>;
    pwm-enable = <1>;
    status = "disable";
};
